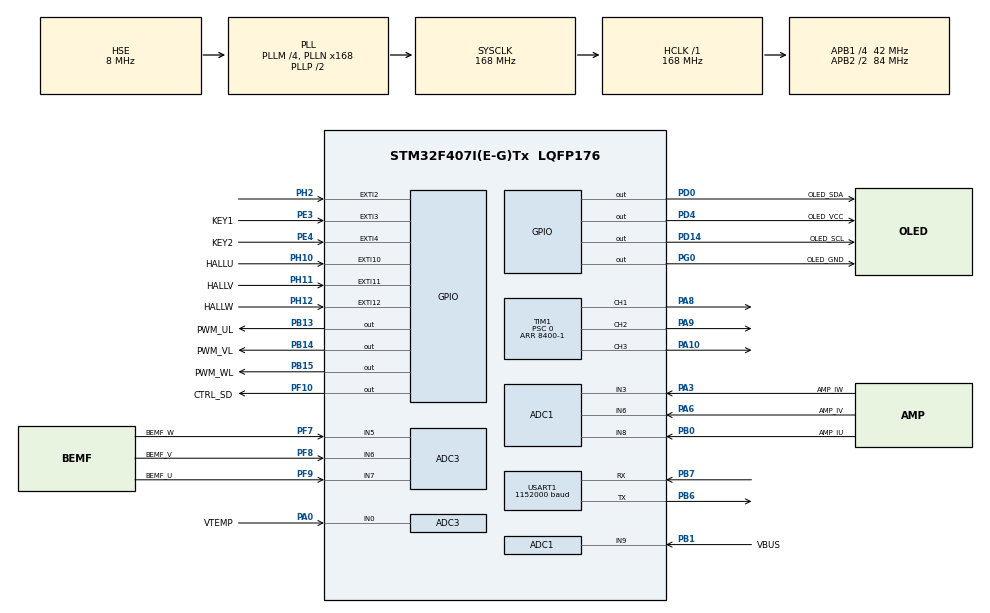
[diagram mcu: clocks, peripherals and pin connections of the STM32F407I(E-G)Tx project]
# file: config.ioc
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ADC1.Channel-0\#ChannelRegularConversion=ADC_CHANNEL_3
ADC1.Channel-1\#ChannelRegularConversion=ADC_CHANNEL_6
ADC1.Channel-2\#ChannelRegularConversion=ADC_CHANNEL_8
ADC1.Channel-3\#ChannelRegularConversion=ADC_CHANNEL_9
ADC1.ContinuousConvMode=ENABLE
ADC1.DMAContinuousRequests=ENABLE
ADC1.DiscontinuousConvMode=DISABLE
ADC1.NbrOfConversion=4
ADC1.NbrOfConversionFlag=1
ADC1.Rank-0\#ChannelRegularConversion=1
ADC1.Rank-1\#ChannelRegularConversion=2
ADC1.Rank-2\#ChannelRegularConversion=3
ADC1.Rank-3\#ChannelRegularConversion=4
ADC1.SamplingTime-0\#ChannelRegularConversion=ADC_SAMPLETIME_56CYCLES
ADC1.SamplingTime-1\#ChannelRegularConversion=ADC_SAMPLETIME_56CYCLES
ADC1.SamplingTime-2\#ChannelRegularConversion=ADC_SAMPLETIME_56CYCLES
ADC1.SamplingTime-3\#ChannelRegularConversion=ADC_SAMPLETIME_56CYCLES
ADC1.ScanConvMode=ENABLE
ADC1.master=1
ADC3.Channel-0\#ChannelRegularConversion=ADC_CHANNEL_0
ADC3.Channel-1\#ChannelRegularConversion=ADC_CHANNEL_5
ADC3.Channel-2\#ChannelRegularConversion=ADC_CHANNEL_6
ADC3.Channel-3\#ChannelRegularConversion=ADC_CHANNEL_7
ADC3.ContinuousConvMode=ENABLE
ADC3.DMAContinuousRequests=ENABLE
ADC3.NbrOfConversion=4
ADC3.NbrOfConversionFlag=1
ADC3.Rank-0\#ChannelRegularConversion=1
ADC3.Rank-1\#ChannelRegularConversion=2
ADC3.Rank-2\#ChannelRegularConversion=3
ADC3.Rank-3\#ChannelRegularConversion=4
ADC3.SamplingTime-0\#ChannelRegularConversion=ADC_SAMPLETIME_56CYCLES
ADC3.SamplingTime-1\#ChannelRegularConversion=ADC_SAMPLETIME_56CYCLES
ADC3.SamplingTime-2\#ChannelRegularConversion=ADC_SAMPLETIME_56CYCLES
ADC3.SamplingTime-3\#ChannelRegularConversion=ADC_SAMPLETIME_56CYCLES
ADC3.ScanConvMode=ENABLE
Dma.ADC1.0.Direction=DMA_PERIPH_TO_MEMORY
Dma.ADC1.0.FIFOMode=DMA_FIFOMODE_DISABLE
Dma.ADC1.0.Instance=DMA2_Stream0
Dma.ADC1.0.MemDataAlignment=DMA_MDATAALIGN_HALFWORD
Dma.ADC1.0.MemInc=DMA_MINC_ENABLE
Dma.ADC1.0.Mode=DMA_CIRCULAR
Dma.ADC1.0.PeriphDataAlignment=DMA_PDATAALIGN_HALFWORD
Dma.ADC1.0.PeriphInc=DMA_PINC_DISABLE
Dma.ADC1.0.Priority=DMA_PRIORITY_MEDIUM
Dma.ADC3.1.Direction=DMA_PERIPH_TO_MEMORY
Dma.ADC3.1.FIFOMode=DMA_FIFOMODE_DISABLE
Dma.ADC3.1.Instance=DMA2_Stream1
Dma.ADC3.1.MemDataAlignment=DMA_MDATAALIGN_HALFWORD
Dma.ADC3.1.MemInc=DMA_MINC_ENABLE
Dma.ADC3.1.Mode=DMA_CIRCULAR
Dma.ADC3.1.PeriphDataAlignment=DMA_PDATAALIGN_HALFWORD
Dma.ADC3.1.PeriphInc=DMA_PINC_DISABLE
Dma.ADC3.1.Priority=DMA_PRIORITY_MEDIUM
Dma.Request0=ADC1
Dma.Request1=ADC3
Dma.Request2=USART1_TX
Dma.USART1_TX.2.Direction=DMA_MEMORY_TO_PERIPH
Dma.USART1_TX.2.FIFOMode=DMA_FIFOMODE_DISABLE
Dma.USART1_TX.2.Instance=DMA2_Stream7
Dma.USART1_TX.2.MemDataAlignment=DMA_MDATAALIGN_BYTE
Dma.USART1_TX.2.MemInc=DMA_MINC_ENABLE
Dma.USART1_TX.2.Mode=DMA_NORMAL
Dma.USART1_TX.2.PeriphDataAlignment=DMA_PDATAALIGN_BYTE
Dma.USART1_TX.2.PeriphInc=DMA_PINC_DISABLE
Dma.USART1_TX.2.Priority=DMA_PRIORITY_HIGH
FREERTOS.Tasks01=MonitorTask,8,512,StartMonitorTask,As weak,NULL,Dynamic,NULL,NULL;BtnStateTask,40,128,StartBtnStateTask,As weak,NULL,Dynamic,NULL,NULL
FREERTOS.configENABLE_FPU=1
FREERTOS.configGENERATE_RUN_TIME_STATS=1
FREERTOS.configRECORD_STACK_HIGH_ADDRESS=1
FREERTOS.configUSE_STATS_FORMATTING_FUNCTIONS=1
Mcu.Family=STM32F4
Mcu.Name=STM32F407I(E-G)Tx
Mcu.Package=LQFP176
NVIC.DMA2_Stream0_IRQn=true\:5\:0\:false\:false\:true\:true\:false\:true\:true
NVIC.DMA2_Stream1_IRQn=true\:5\:0\:false\:false\:true\:true\:false\:true\:true
NVIC.DMA2_Stream7_IRQn=true\:5\:0\:false\:false\:true\:true\:false\:true\:true
NVIC.EXTI15_10_IRQn=true\:5\:0\:false\:false\:true\:true\:true\:true\:true
NVIC.EXTI2_IRQn=true\:5\:0\:false\:false\:true\:true\:true\:true\:true
NVIC.EXTI3_IRQn=true\:5\:0\:false\:false\:true\:true\:true\:true\:true
NVIC.EXTI4_IRQn=true\:5\:0\:false\:false\:true\:true\:true\:true\:true
NVIC.PriorityGroup=NVIC_PRIORITYGROUP_4
NVIC.TIM1_UP_TIM10_IRQn=true\:5\:0\:false\:false\:true\:true\:true\:true\:true
NVIC.TIM4_IRQn=true\:15\:0\:false\:false\:true\:false\:false\:true\:true
NVIC.TIM5_IRQn=true\:5\:0\:false\:false\:true\:true\:true\:true\:true
NVIC.TimeBase=TIM4_IRQn
NVIC.TimeBaseIP=TIM4
NVIC.USART1_IRQn=true\:5\:0\:false\:false\:true\:true\:true\:true\:true
PA0-WKUP.GPIO_Label=VTEMP
PA0-WKUP.Signal=ADCx_IN0
PA10.GPIO_Speed=GPIO_SPEED_FREQ_VERY_HIGH
PA10.Signal=S_TIM1_CH3
PA13.Mode=Serial_Wire
PA13.Signal=SYS_JTMS-SWDIO
PA14.Mode=Serial_Wire
PA14.Signal=SYS_JTCK-SWCLK
PA3.GPIO_Label=AMP_IW
PA3.Signal=ADCx_IN3
PA6.GPIO_Label=AMP_IV
PA6.Signal=ADCx_IN6
PA8.GPIO_Speed=GPIO_SPEED_FREQ_VERY_HIGH
PA8.Signal=S_TIM1_CH1
PA9.GPIO_Speed=GPIO_SPEED_FREQ_VERY_HIGH
PA9.Signal=S_TIM1_CH2
PB0.GPIO_Label=AMP_IU
PB0.Signal=ADCx_IN8
PB1.GPIO_Label=VBUS
PB1.Signal=ADCx_IN9
PB13.GPIO_Label=PWM_UL
PB13.GPIO_PuPd=GPIO_NOPULL
PB13.GPIO_Speed=GPIO_SPEED_FREQ_VERY_HIGH
PB13.PinState=GPIO_PIN_RESET
PB13.Signal=GPIO_Output
PB14.GPIO_Label=PWM_VL
PB14.GPIO_Speed=GPIO_SPEED_FREQ_VERY_HIGH
PB14.Signal=GPIO_Output
PB15.GPIO_Label=PWM_WL
PB15.GPIO_Speed=GPIO_SPEED_FREQ_VERY_HIGH
PB15.Signal=GPIO_Output
PB6.Mode=Asynchronous
PB6.Signal=USART1_TX
PB7.Mode=Asynchronous
PB7.Signal=USART1_RX
PD0.GPIO_Label=OLED_SDA
PD0.GPIO_ModeDefaultOutputPP=GPIO_MODE_OUTPUT_OD
PD0.GPIO_PuPd=GPIO_NOPULL
PD0.GPIO_Speed=GPIO_SPEED_FREQ_VERY_HIGH
PD0.PinState=GPIO_PIN_SET
PD0.Signal=GPIO_Output
PD14.GPIO_Label=OLED_SCL
PD14.GPIO_ModeDefaultOutputPP=GPIO_MODE_OUTPUT_OD
PD14.GPIO_PuPd=GPIO_NOPULL
PD14.GPIO_Speed=GPIO_SPEED_FREQ_VERY_HIGH
PD14.PinState=GPIO_PIN_SET
PD14.Signal=GPIO_Output
PD4.GPIO_Label=OLED_VCC
PD4.GPIO_ModeDefaultOutputPP=GPIO_MODE_OUTPUT_PP
PD4.GPIO_PuPd=GPIO_PULLUP
PD4.GPIO_Speed=GPIO_SPEED_FREQ_LOW
PD4.PinState=GPIO_PIN_SET
PD4.Signal=GPIO_Output
PE3.GPIO_Label=KEY1
PE3.GPIO_ModeDefaultEXTI=GPIO_MODE_IT_FALLING
PE3.GPIO_PuPd=GPIO_PULLUP
PE3.Signal=GPXTI3
PE4.GPIO_Label=KEY2
PE4.GPIO_ModeDefaultEXTI=GPIO_MODE_IT_FALLING
PE4.GPIO_PuPd=GPIO_PULLUP
PE4.Signal=GPXTI4
PF10.GPIO_Label=CTRL_SD
PF10.GPIO_Speed=GPIO_SPEED_FREQ_VERY_HIGH
PF10.PinState=GPIO_PIN_SET
PF10.Signal=GPIO_Output
PF7.GPIO_Label=BEMF_W
PF7.Mode=IN5
PF7.Signal=ADC3_IN5
PF8.GPIO_Label=BEMF_V
PF8.Mode=IN6
PF8.Signal=ADC3_IN6
PF9.GPIO_Label=BEMF_U
PF9.Mode=IN7
PF9.Signal=ADC3_IN7
PG0.GPIO_Label=OLED_GND
PG0.GPIO_ModeDefaultOutputPP=GPIO_MODE_OUTPUT_OD
PG0.GPIO_PuPd=GPIO_NOPULL
PG0.GPIO_Speed=GPIO_SPEED_FREQ_LOW
PG0.Signal=GPIO_Output
PH0-OSC_IN.Mode=HSE-External-Oscillator
PH0-OSC_IN.Signal=RCC_OSC_IN
PH1-OSC_OUT.Mode=HSE-External-Oscillator
PH1-OSC_OUT.Signal=RCC_OSC_OUT
PH10.GPIO_Label=HALLU
PH10.GPIO_ModeDefaultEXTI=GPIO_MODE_IT_RISING_FALLING
PH10.GPIO_PuPd=GPIO_PULLUP
PH10.Signal=GPXTI10
PH11.GPIO_Label=HALLV
PH11.GPIO_ModeDefaultEXTI=GPIO_MODE_IT_RISING_FALLING
PH11.GPIO_PuPd=GPIO_PULLUP
PH11.Signal=GPXTI11
PH12.GPIO_Label=HALLW
PH12.GPIO_ModeDefaultEXTI=GPIO_MODE_IT_RISING_FALLING
PH12.GPIO_PuPd=GPIO_PULLUP
PH12.Signal=GPXTI12
PH2.Signal=GPXTI2
ProjectManager.HeapSize=0x200
ProjectManager.StackSize=0x400
ProjectManager.TargetToolchain=CMake
RCC.48MHZClocksFreq_Value=84000000
RCC.AHBFreq_Value=168000000
RCC.APB1CLKDivider=RCC_HCLK_DIV4
RCC.APB1Freq_Value=42000000
RCC.APB1TimFreq_Value=84000000
RCC.APB2CLKDivider=RCC_HCLK_DIV2
RCC.APB2Freq_Value=84000000
RCC.APB2TimFreq_Value=168000000
RCC.CortexFreq_Value=168000000
RCC.HCLKFreq_Value=168000000
RCC.HSE_VALUE=8000000
RCC.HSI_VALUE=16000000
RCC.LSE_VALUE=32768
RCC.PLLM=4
RCC.PLLN=168
RCC.PLLSourceVirtual=RCC_PLLSOURCE_HSE
RCC.SYSCLKFreq_VALUE=168000000
RCC.SYSCLKSource=RCC_SYSCLKSOURCE_PLLCLK
RCC.VCOOutputFreq_Value=336000000
SH.ADCx_IN0.0=ADC3_IN0,IN0
SH.ADCx_IN3.0=ADC1_IN3,IN3
SH.ADCx_IN6.0=ADC1_IN6,IN6
SH.ADCx_IN8.0=ADC1_IN8,IN8
SH.ADCx_IN9.0=ADC1_IN9,IN9
SH.S_TIM1_CH1.0=TIM1_CH1,PWM Generation1 CH1
SH.S_TIM1_CH2.0=TIM1_CH2,PWM Generation2 CH2
SH.S_TIM1_CH3.0=TIM1_CH3,PWM Generation3 CH3
TIM1.AutoReloadPreload=TIM_AUTORELOAD_PRELOAD_ENABLE
TIM1.Channel-PWM\ Generation1\ CH1=TIM_CHANNEL_1
TIM1.Channel-PWM\ Generation2\ CH2=TIM_CHANNEL_2
TIM1.Channel-PWM\ Generation3\ CH3=TIM_CHANNEL_3
TIM1.OCFastMode_PWM-PWM\ Generation1\ CH1=TIM_OCFAST_ENABLE
TIM1.OCFastMode_PWM-PWM\ Generation2\ CH2=TIM_OCFAST_ENABLE
TIM1.OCFastMode_PWM-PWM\ Generation3\ CH3=TIM_OCFAST_ENABLE
TIM1.Period=8400-1
TIM1.Prescaler=0
TIM1.Pulse-PWM\ Generation1\ CH1=10
TIM1.Pulse-PWM\ Generation2\ CH2=10
TIM1.Pulse-PWM\ Generation3\ CH3=10
TIM5.Prescaler=84-1
USART1.BaudRate=1152000
USART1.VirtualMode=VM_ASYNC
VP_FREERTOS_VS_CMSIS_V2.Mode=CMSIS_V2
VP_SYS_VS_tim4.Mode=TIM4
VP_TIM1_VS_ClockSourceINT.Mode=Internal
VP_TIM5_VS_ClockSourceINT.Mode=Internal
board=custom

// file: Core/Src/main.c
/* USER CODE BEGIN Header */
/**
  ******************************************************************************
  * @file           : main.c
  * @brief          : Main program body
  ******************************************************************************
  * @attention
  *
  * Copyright (c) 2026 STMicroelectronics.
  * All rights reserved.
  *
  * This software is licensed under terms that can be found in the LICENSE file
  * in the root directory of this software component.
  * If no LICENSE file comes with this software, it is provided AS-IS.
  *
  ******************************************************************************
  */
/* USER CODE END Header */
#include "main.h"
#include "cmsis_os.h"
#include "adc.h"
#include "dma.h"
#include "tim.h"
#include "usart.h"
#include "gpio.h"

/* USER CODE BEGIN Includes */
#include "motorCtrl.h"
/* USER CODE END Includes */

void SystemClock_Config(void);
void MX_FREERTOS_Init(void);

int main(void)
{

  /* MCU Configuration--------------------------------------------------------*/

  /* Reset of all peripherals, Initializes the Flash interface and the Systick. */
  HAL_Init();

  /* Configure the system clock */
  SystemClock_Config();

  /* Initialize all configured peripherals */
  MX_GPIO_Init();
  MX_DMA_Init();
  MX_USART1_UART_Init();
  MX_ADC1_Init();
  MX_ADC3_Init();
  MX_TIM1_Init();
  MX_TIM5_Init();

  /* Init scheduler */
  osKernelInitialize();  /* Call init function for freertos objects (in cmsis_os2.c) */
  MX_FREERTOS_Init();

  /* Start scheduler */
  osKernelStart();

  /* We should never get here as control is now taken by the scheduler */

  /* Infinite loop */
  while (1)
  {

  }
}

void SystemClock_Config(void)
{
  RCC_OscInitTypeDef RCC_OscInitStruct = {0};
  RCC_ClkInitTypeDef RCC_ClkInitStruct = {0};

  /** Configure the main internal regulator output voltage
  */
  __HAL_RCC_PWR_CLK_ENABLE();
  __HAL_PWR_VOLTAGESCALING_CONFIG(PWR_REGULATOR_VOLTAGE_SCALE1);

  /** Initializes the RCC Oscillators according to the specified parameters
  * in the RCC_OscInitTypeDef structure.
  */
  RCC_OscInitStruct.OscillatorType = RCC_OSCILLATORTYPE_HSE;
  RCC_OscInitStruct.HSEState = RCC_HSE_ON;
  RCC_OscInitStruct.PLL.PLLState = RCC_PLL_ON;
  RCC_OscInitStruct.PLL.PLLSource = RCC_PLLSOURCE_HSE;
  RCC_OscInitStruct.PLL.PLLM = 4;
  RCC_OscInitStruct.PLL.PLLN = 168;
  RCC_OscInitStruct.PLL.PLLP = RCC_PLLP_DIV2;
  RCC_OscInitStruct.PLL.PLLQ = 4;
  if (HAL_RCC_OscConfig(&RCC_OscInitStruct) != HAL_OK)
  {
    Error_Handler();
  }

  /** Initializes the CPU, AHB and APB buses clocks
  */
  RCC_ClkInitStruct.ClockType = RCC_CLOCKTYPE_HCLK|RCC_CLOCKTYPE_SYSCLK
                              |RCC_CLOCKTYPE_PCLK1|RCC_CLOCKTYPE_PCLK2;
  RCC_ClkInitStruct.SYSCLKSource = RCC_SYSCLKSOURCE_PLLCLK;
  RCC_ClkInitStruct.AHBCLKDivider = RCC_SYSCLK_DIV1;
  RCC_ClkInitStruct.APB1CLKDivider = RCC_HCLK_DIV4;
  RCC_ClkInitStruct.APB2CLKDivider = RCC_HCLK_DIV2;

  if (HAL_RCC_ClockConfig(&RCC_ClkInitStruct, FLASH_LATENCY_5) != HAL_OK)
  {
    Error_Handler();
  }
}

void HAL_TIM_PeriodElapsedCallback(TIM_HandleTypeDef *htim)
{
  /* USER CODE BEGIN Callback 0 */
  if (htim->Instance == TIM1)
  {
    motorCtrl_PWMCallback(motorCtrl_GetDirection());
  }
  /* USER CODE END Callback 0 */
  if (htim->Instance == TIM4)
  {
    HAL_IncTick();
  }
}

void Error_Handler(void)
{
  __disable_irq();
  while (1)
  {
  }
}

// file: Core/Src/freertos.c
/* USER CODE BEGIN Header */
/**
  ******************************************************************************
  * File Name          : freertos.c
  * Description        : Code for freertos applications
  ******************************************************************************
  * @attention
  *
  * Copyright (c) 2026 STMicroelectronics.
  * All rights reserved.
  *
  * This software is licensed under terms that can be found in the LICENSE file
  * in the root directory of this software component.
  * If no LICENSE file comes with this software, it is provided AS-IS.
  *
  ******************************************************************************
  */
/* USER CODE END Header */

#include "FreeRTOS.h"
#include "task.h"
#include "main.h"
#include "cmsis_os.h"

/* USER CODE BEGIN Includes */
#include "monitor.h"

/* USER CODE END Includes */

/* Definitions for MonitorTask */
osThreadId_t MonitorTaskHandle;
const osThreadAttr_t MonitorTask_attributes = {
  .name = "MonitorTask",
  .stack_size = 512 * 4,
  .priority = (osPriority_t) osPriorityLow,
};
/* Definitions for BtnStateTask */
osThreadId_t BtnStateTaskHandle;
const osThreadAttr_t BtnStateTask_attributes = {
  .name = "BtnStateTask",
  .stack_size = 128 * 4,
  .priority = (osPriority_t) osPriorityHigh,
};

void StartMonitorTask(void *argument);
void StartBtnStateTask(void *argument);

void MX_FREERTOS_Init(void); /* (MISRA C 2004 rule 8.1) */

/* Hook prototypes */
void configureTimerForRunTimeStats(void);
unsigned long getRunTimeCounterValue(void);

/* USER CODE BEGIN 1 */
/* Functions needed when configGENERATE_RUN_TIME_STATS is on */
void configureTimerForRunTimeStats(void)
{
  CoreDebug->DEMCR |= CoreDebug_DEMCR_TRCENA_Msk;
  DWT->CYCCNT = 0;
  DWT->CTRL |= DWT_CTRL_CYCCNTENA_Msk;
}

unsigned long getRunTimeCounterValue(void)
{
  return DWT->CYCCNT;
}
/* USER CODE END 1 */

void MX_FREERTOS_Init(void) {

  /* Create the thread(s) */
  /* creation of MonitorTask */
  MonitorTaskHandle = osThreadNew(StartMonitorTask, NULL, &MonitorTask_attributes);

  /* creation of BtnStateTask */
  BtnStateTaskHandle = osThreadNew(StartBtnStateTask, NULL, &BtnStateTask_attributes);

}

__weak void StartMonitorTask(void *argument)
{
  for(;;)
  {
    osDelay(1);
  }
}

__weak void StartBtnStateTask(void *argument)
{
  for(;;)
  {
    osDelay(1);
  }
}
